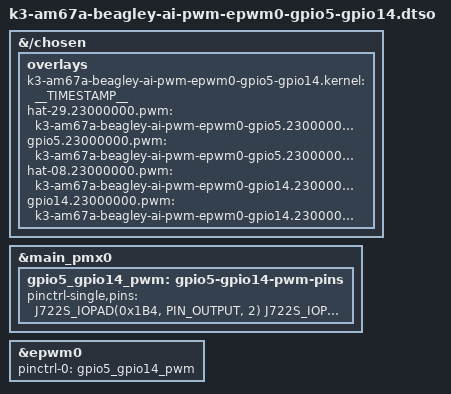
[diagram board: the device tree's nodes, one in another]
// SPDX-License-Identifier: GPL-2.0-only OR MIT
/*
 * DT Overlay for GPIO5 and GPIO14 epwm0 connections within the expansion header.
 *
 * Copyright (C) 2023 Texas Instruments Incorporated - https://www.ti.com/
 *
 */

/dts-v1/;
/plugin/;

#include <dt-bindings/gpio/gpio.h>
#include "k3-pinctrl.h"

/*
 * Helper to show loaded overlays under: /proc/device-tree/chosen/overlays/
*/
&{/chosen} {
	overlays {
		k3-am67a-beagley-ai-pwm-epwm0-gpio5-gpio14.kernel = __TIMESTAMP__;
		hat-29.23000000.pwm = "k3-am67a-beagley-ai-pwm-epwm0-gpio5.23000000.0.GPIO5";
		gpio5.23000000.pwm = "k3-am67a-beagley-ai-pwm-epwm0-gpio5.23000000.0.GPIO5";
		hat-08.23000000.pwm = "k3-am67a-beagley-ai-pwm-epwm0-gpio14.23000000.1.GPIO14";
		gpio14.23000000.pwm = "k3-am67a-beagley-ai-pwm-epwm0-gpio14.23000000.1.GPIO14";
	};
};

&main_pmx0 {
	gpio5_gpio14_pwm: gpio5-gpio14-pwm-pins {
		pinctrl-single,pins = <
			J722S_IOPAD(0x1B4, PIN_OUTPUT, 2) /* (B20) SPI0_CS0.EHRPWM0_A */
			J722S_IOPAD(0x1B0, PIN_OUTPUT, 6) /* (F24) MCASP0_ACLKR.EHRPWM0_B */
		>;
	};
};

&epwm0 {
	pinctrl-names = "default";
	pinctrl-0 = <&gpio5_gpio14_pwm>;
	status = "okay";
};
